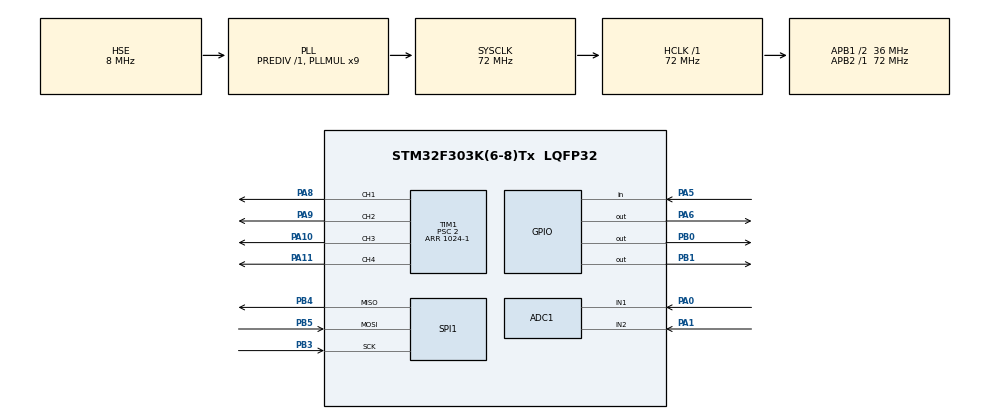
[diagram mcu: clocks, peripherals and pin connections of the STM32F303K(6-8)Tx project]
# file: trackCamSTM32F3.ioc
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ADC1.Channel-0\#ChannelRegularConversion=ADC_CHANNEL_1
ADC1.Channel-1\#ChannelRegularConversion=ADC_CHANNEL_2
ADC1.ClockPrescaler=ADC_CLOCK_SYNC_PCLK_DIV2
ADC1.ContinuousConvMode=ENABLE
ADC1.DMAAccessModeView=ENABLE
ADC1.DMAContinuousRequests=ENABLE
ADC1.EnableInjectedConversion=DISABLE
ADC1.NbrOfConversion=2
ADC1.NbrOfConversionFlag=1
ADC1.Offset-0\#ChannelRegularConversion=0
ADC1.Offset-1\#ChannelRegularConversion=0
ADC1.OffsetNumber-0\#ChannelRegularConversion=ADC_OFFSET_NONE
ADC1.OffsetNumber-1\#ChannelRegularConversion=ADC_OFFSET_NONE
ADC1.Overrun=ADC_OVR_DATA_PRESERVED
ADC1.Rank-0\#ChannelRegularConversion=1
ADC1.Rank-1\#ChannelRegularConversion=2
ADC1.SamplingTime-0\#ChannelRegularConversion=ADC_SAMPLETIME_19CYCLES_5
ADC1.SamplingTime-1\#ChannelRegularConversion=ADC_SAMPLETIME_19CYCLES_5
ADC1.SubFamily=STM32F303x8
ADC1.master=1
Dma.ADC1.0.Direction=DMA_PERIPH_TO_MEMORY
Dma.ADC1.0.Instance=DMA1_Channel1
Dma.ADC1.0.MemDataAlignment=DMA_MDATAALIGN_HALFWORD
Dma.ADC1.0.MemInc=DMA_MINC_ENABLE
Dma.ADC1.0.Mode=DMA_CIRCULAR
Dma.ADC1.0.PeriphDataAlignment=DMA_PDATAALIGN_HALFWORD
Dma.ADC1.0.PeriphInc=DMA_PINC_DISABLE
Dma.ADC1.0.Priority=DMA_PRIORITY_LOW
Dma.Request0=ADC1
Mcu.Family=STM32F3
Mcu.Name=STM32F303K(6-8)Tx
Mcu.Package=LQFP32
NVIC.DMA1_Channel1_IRQn=true\:0\:0\:false\:false\:true
NVIC.PriorityGroup=NVIC_PRIORITYGROUP_4
NVIC.TIM2_IRQn=true\:0\:0\:false\:false\:true
PA0.Mode=IN1-Single-Ended
PA0.Signal=ADC1_IN1
PA1.Mode=IN2-Single-Ended
PA1.Signal=ADC1_IN2
PA10.Signal=S_TIM1_CH3
PA11.Signal=S_TIM1_CH4
PA13.Mode=Serial_Wire
PA13.Signal=SYS_JTMS-SWDIO
PA14.Mode=Serial_Wire
PA14.Signal=SYS_JTCK-SWCLK
PA5.Signal=GPIO_Input
PA6.Signal=GPIO_Output
PA8.Signal=S_TIM1_CH1
PA9.Signal=S_TIM1_CH2
PB0.Signal=GPIO_Output
PB1.Signal=GPIO_Output
PB3.Mode=Full_Duplex_Slave
PB3.Signal=SPI1_SCK
PB4.Mode=Full_Duplex_Slave
PB4.Signal=SPI1_MISO
PB5.Mode=Full_Duplex_Slave
PB5.Signal=SPI1_MOSI
PF0\ /\ OSC_IN.Mode=HSE-External-Oscillator
PF0\ /\ OSC_IN.Signal=RCC_OSC_IN
PF1\ /\ OSC_OUT.Mode=HSE-External-Oscillator
PF1\ /\ OSC_OUT.Signal=RCC_OSC_OUT
ProjectManager.HeapSize=0x200
ProjectManager.StackSize=0x400
ProjectManager.TargetToolchain=SW4STM32
RCC.AHBFreq_Value=72000000
RCC.APB1CLKDivider=RCC_HCLK_DIV2
RCC.APB1Freq_Value=36000000
RCC.APB1TimFreq_Value=72000000
RCC.APB2Freq_Value=72000000
RCC.APB2TimFreq_Value=72000000
RCC.CortexFreq_Value=72000000
RCC.HCLKFreq_Value=72000000
RCC.HSE_VALUE=8000000
RCC.HSIState=RCC_HSI_ON
RCC.HSI_VALUE=8000000
RCC.PLLMUL=RCC_PLL_MUL9
RCC.PLLSourceVirtual=RCC_PLLSOURCE_HSE
RCC.SYSCLKFreq_VALUE=72000000
RCC.SYSCLKSourceVirtual=RCC_SYSCLKSOURCE_PLLCLK
SH.S_TIM1_CH1.0=TIM1_CH1,PWM Generation1 CH1
SH.S_TIM1_CH2.0=TIM1_CH2,PWM Generation2 CH2
SH.S_TIM1_CH3.0=TIM1_CH3,PWM Generation3 CH3
SH.S_TIM1_CH4.0=TIM1_CH4,PWM Generation4 CH4
SPI1.DataSize=SPI_DATASIZE_8BIT
SPI1.VirtualType=VM_SLAVE
TIM1.Channel-PWM\ Generation2\ CH2=TIM_CHANNEL_2
TIM1.Channel-PWM\ Generation3\ CH3=TIM_CHANNEL_3
TIM1.Channel-PWM\ Generation4\ CH4=TIM_CHANNEL_4
TIM1.Period=1024-1
TIM1.Prescaler=2
TIM2.Period=500-1
TIM2.Prescaler=7200
VP_TIM2_VS_ClockSourceINT.Mode=Internal
board=trackCamSTM32F3

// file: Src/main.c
/**
  ******************************************************************************
  * File Name          : main.c
  * Description        : Main program body
  ******************************************************************************
  *
  * COPYRIGHT(c) 2017 STMicroelectronics
  *
  * Redistribution and use in source and binary forms, with or without modification,
  * are permitted provided that the following conditions are met:
  *   1. Redistributions of source code must retain the above copyright notice,
  *      this list of conditions and the following disclaimer.
  *   2. Redistributions in binary form must reproduce the above copyright notice,
  *      this list of conditions and the following disclaimer in the documentation
  *      and/or other materials provided with the distribution.
  *   3. Neither the name of STMicroelectronics nor the names of its contributors
  *      may be used to endorse or promote products derived from this software
  *      without specific prior written permission.
  *
  * THIS SOFTWARE IS PROVIDED BY THE COPYRIGHT HOLDERS AND CONTRIBUTORS "AS IS"
  * AND ANY EXPRESS OR IMPLIED WARRANTIES, INCLUDING, BUT NOT LIMITED TO, THE
  * IMPLIED WARRANTIES OF MERCHANTABILITY AND FITNESS FOR A PARTICULAR PURPOSE ARE
  * DISCLAIMED. IN NO EVENT SHALL THE COPYRIGHT HOLDER OR CONTRIBUTORS BE LIABLE
  * FOR ANY DIRECT, INDIRECT, INCIDENTAL, SPECIAL, EXEMPLARY, OR CONSEQUENTIAL
  * DAMAGES (INCLUDING, BUT NOT LIMITED TO, PROCUREMENT OF SUBSTITUTE GOODS OR
  * SERVICES; LOSS OF USE, DATA, OR PROFITS; OR BUSINESS INTERRUPTION) HOWEVER
  * CAUSED AND ON ANY THEORY OF LIABILITY, WHETHER IN CONTRACT, STRICT LIABILITY,
  * OR TORT (INCLUDING NEGLIGENCE OR OTHERWISE) ARISING IN ANY WAY OUT OF THE USE
  * OF THIS SOFTWARE, EVEN IF ADVISED OF THE POSSIBILITY OF SUCH DAMAGE.
  *
  ******************************************************************************
  */
#include "main.h"
#include "stm32f3xx_hal.h"

/* USER CODE BEGIN Includes */
#include "TrackCam.h"
/* USER CODE END Includes */

ADC_HandleTypeDef hadc1;
DMA_HandleTypeDef hdma_adc1;

SPI_HandleTypeDef hspi1;

TIM_HandleTypeDef htim1;
TIM_HandleTypeDef htim2;

/* USER CODE BEGIN PV */
/* Private variables ---------------------------------------------------------*/

/* USER CODE END PV */

void SystemClock_Config(void);
void Error_Handler(void);
static void MX_GPIO_Init(void);
static void MX_DMA_Init(void);
static void MX_ADC1_Init(void);
static void MX_SPI1_Init(void);
static void MX_TIM1_Init(void);
static void MX_TIM2_Init(void);

void HAL_TIM_MspPostInit(TIM_HandleTypeDef *htim);

/* USER CODE BEGIN PFP */
/* Private function prototypes -----------------------------------------------*/

/* USER CODE END PFP */

int main(void)
{

  /* MCU Configuration----------------------------------------------------------*/

  /* Reset of all peripherals, Initializes the Flash interface and the Systick. */
  HAL_Init();

  /* Configure the system clock */
  SystemClock_Config();

  /* Initialize all configured peripherals */
  MX_GPIO_Init();
  MX_DMA_Init();
  MX_ADC1_Init();
  MX_SPI1_Init();
  MX_TIM1_Init();
  MX_TIM2_Init();

  /* Infinite loop */
  /* USER CODE BEGIN WHILE */
  TrackCamContext c;
  c.hadc = &hadc1;
  c.hspi = &hspi1;
  c.htimLed = &htim2;
  c.htimMotor = &htim1;
  trackCamMain(&c);
  /* USER CODE END WHILE */

}

/** System Clock Configuration
*/
void SystemClock_Config(void)
{

  RCC_OscInitTypeDef RCC_OscInitStruct;
  RCC_ClkInitTypeDef RCC_ClkInitStruct;
  RCC_PeriphCLKInitTypeDef PeriphClkInit;

    /**Initializes the CPU, AHB and APB busses clocks
    */
  RCC_OscInitStruct.OscillatorType = RCC_OSCILLATORTYPE_HSE;
  RCC_OscInitStruct.HSEState = RCC_HSE_ON;
  RCC_OscInitStruct.HSEPredivValue = RCC_HSE_PREDIV_DIV1;
  RCC_OscInitStruct.HSIState = RCC_HSI_ON;
  RCC_OscInitStruct.PLL.PLLState = RCC_PLL_ON;
  RCC_OscInitStruct.PLL.PLLSource = RCC_PLLSOURCE_HSE;
  RCC_OscInitStruct.PLL.PLLMUL = RCC_PLL_MUL9;
  if (HAL_RCC_OscConfig(&RCC_OscInitStruct) != HAL_OK)
  {
    Error_Handler();
  }

    /**Initializes the CPU, AHB and APB busses clocks
    */
  RCC_ClkInitStruct.ClockType = RCC_CLOCKTYPE_HCLK|RCC_CLOCKTYPE_SYSCLK
                              |RCC_CLOCKTYPE_PCLK1|RCC_CLOCKTYPE_PCLK2;
  RCC_ClkInitStruct.SYSCLKSource = RCC_SYSCLKSOURCE_PLLCLK;
  RCC_ClkInitStruct.AHBCLKDivider = RCC_SYSCLK_DIV1;
  RCC_ClkInitStruct.APB1CLKDivider = RCC_HCLK_DIV2;
  RCC_ClkInitStruct.APB2CLKDivider = RCC_HCLK_DIV1;

  if (HAL_RCC_ClockConfig(&RCC_ClkInitStruct, FLASH_LATENCY_2) != HAL_OK)
  {
    Error_Handler();
  }

  PeriphClkInit.PeriphClockSelection = RCC_PERIPHCLK_TIM1;
  PeriphClkInit.Tim1ClockSelection = RCC_TIM1CLK_HCLK;
  if (HAL_RCCEx_PeriphCLKConfig(&PeriphClkInit) != HAL_OK)
  {
    Error_Handler();
  }

    /**Configure the Systick interrupt time
    */
  HAL_SYSTICK_Config(HAL_RCC_GetHCLKFreq()/1000);

    /**Configure the Systick
    */
  HAL_SYSTICK_CLKSourceConfig(SYSTICK_CLKSOURCE_HCLK);

  /* SysTick_IRQn interrupt configuration */
  HAL_NVIC_SetPriority(SysTick_IRQn, 0, 0);
}

/* ADC1 init function */
static void MX_ADC1_Init(void)
{

  ADC_MultiModeTypeDef multimode;
  ADC_ChannelConfTypeDef sConfig;

    /**Common config
    */
  hadc1.Instance = ADC1;
  hadc1.Init.ClockPrescaler = ADC_CLOCK_SYNC_PCLK_DIV2;
  hadc1.Init.Resolution = ADC_RESOLUTION_12B;
  hadc1.Init.ScanConvMode = ADC_SCAN_ENABLE;
  hadc1.Init.ContinuousConvMode = ENABLE;
  hadc1.Init.DiscontinuousConvMode = DISABLE;
  hadc1.Init.ExternalTrigConvEdge = ADC_EXTERNALTRIGCONVEDGE_NONE;
  hadc1.Init.ExternalTrigConv = ADC_SOFTWARE_START;
  hadc1.Init.DataAlign = ADC_DATAALIGN_RIGHT;
  hadc1.Init.NbrOfConversion = 2;
  hadc1.Init.DMAContinuousRequests = ENABLE;
  hadc1.Init.EOCSelection = ADC_EOC_SINGLE_CONV;
  hadc1.Init.LowPowerAutoWait = DISABLE;
  hadc1.Init.Overrun = ADC_OVR_DATA_PRESERVED;
  if (HAL_ADC_Init(&hadc1) != HAL_OK)
  {
    Error_Handler();
  }

    /**Configure the ADC multi-mode
    */
  multimode.DMAAccessMode = ADC_DMAACCESSMODE_12_10_BITS;
  multimode.TwoSamplingDelay = ADC_TWOSAMPLINGDELAY_1CYCLE;
  if (HAL_ADCEx_MultiModeConfigChannel(&hadc1, &multimode) != HAL_OK)
  {
    Error_Handler();
  }

    /**Configure Regular Channel
    */
  sConfig.Channel = ADC_CHANNEL_1;
  sConfig.Rank = 1;
  sConfig.SingleDiff = ADC_SINGLE_ENDED;
  sConfig.SamplingTime = ADC_SAMPLETIME_19CYCLES_5;
  sConfig.OffsetNumber = ADC_OFFSET_NONE;
  sConfig.Offset = 0;
  if (HAL_ADC_ConfigChannel(&hadc1, &sConfig) != HAL_OK)
  {
    Error_Handler();
  }

    /**Configure Regular Channel
    */
  sConfig.Channel = ADC_CHANNEL_2;
  sConfig.Rank = 2;
  if (HAL_ADC_ConfigChannel(&hadc1, &sConfig) != HAL_OK)
  {
    Error_Handler();
  }

}

/* SPI1 init function */
static void MX_SPI1_Init(void)
{

  hspi1.Instance = SPI1;
  hspi1.Init.Mode = SPI_MODE_SLAVE;
  hspi1.Init.Direction = SPI_DIRECTION_2LINES;
  hspi1.Init.DataSize = SPI_DATASIZE_8BIT;
  hspi1.Init.CLKPolarity = SPI_POLARITY_LOW;
  hspi1.Init.CLKPhase = SPI_PHASE_1EDGE;
  hspi1.Init.NSS = SPI_NSS_SOFT;
  hspi1.Init.FirstBit = SPI_FIRSTBIT_MSB;
  hspi1.Init.TIMode = SPI_TIMODE_DISABLE;
  hspi1.Init.CRCCalculation = SPI_CRCCALCULATION_DISABLE;
  hspi1.Init.CRCPolynomial = 7;
  hspi1.Init.CRCLength = SPI_CRC_LENGTH_DATASIZE;
  hspi1.Init.NSSPMode = SPI_NSS_PULSE_DISABLE;
  if (HAL_SPI_Init(&hspi1) != HAL_OK)
  {
    Error_Handler();
  }

}

/* TIM1 init function */
static void MX_TIM1_Init(void)
{

  TIM_MasterConfigTypeDef sMasterConfig;
  TIM_OC_InitTypeDef sConfigOC;
  TIM_BreakDeadTimeConfigTypeDef sBreakDeadTimeConfig;

  htim1.Instance = TIM1;
  htim1.Init.Prescaler = 2;
  htim1.Init.CounterMode = TIM_COUNTERMODE_UP;
  htim1.Init.Period = 1024-1;
  htim1.Init.ClockDivision = TIM_CLOCKDIVISION_DIV1;
  htim1.Init.RepetitionCounter = 0;
  htim1.Init.AutoReloadPreload = TIM_AUTORELOAD_PRELOAD_DISABLE;
  if (HAL_TIM_PWM_Init(&htim1) != HAL_OK)
  {
    Error_Handler();
  }

  sMasterConfig.MasterOutputTrigger = TIM_TRGO_RESET;
  sMasterConfig.MasterOutputTrigger2 = TIM_TRGO2_RESET;
  sMasterConfig.MasterSlaveMode = TIM_MASTERSLAVEMODE_DISABLE;
  if (HAL_TIMEx_MasterConfigSynchronization(&htim1, &sMasterConfig) != HAL_OK)
  {
    Error_Handler();
  }

  sConfigOC.OCMode = TIM_OCMODE_PWM1;
  sConfigOC.Pulse = 0;
  sConfigOC.OCPolarity = TIM_OCPOLARITY_HIGH;
  sConfigOC.OCNPolarity = TIM_OCNPOLARITY_HIGH;
  sConfigOC.OCFastMode = TIM_OCFAST_DISABLE;
  sConfigOC.OCIdleState = TIM_OCIDLESTATE_RESET;
  sConfigOC.OCNIdleState = TIM_OCNIDLESTATE_RESET;
  if (HAL_TIM_PWM_ConfigChannel(&htim1, &sConfigOC, TIM_CHANNEL_1) != HAL_OK)
  {
    Error_Handler();
  }

  if (HAL_TIM_PWM_ConfigChannel(&htim1, &sConfigOC, TIM_CHANNEL_2) != HAL_OK)
  {
    Error_Handler();
  }

  if (HAL_TIM_PWM_ConfigChannel(&htim1, &sConfigOC, TIM_CHANNEL_3) != HAL_OK)
  {
    Error_Handler();
  }

  if (HAL_TIM_PWM_ConfigChannel(&htim1, &sConfigOC, TIM_CHANNEL_4) != HAL_OK)
  {
    Error_Handler();
  }

  sBreakDeadTimeConfig.OffStateRunMode = TIM_OSSR_DISABLE;
  sBreakDeadTimeConfig.OffStateIDLEMode = TIM_OSSI_DISABLE;
  sBreakDeadTimeConfig.LockLevel = TIM_LOCKLEVEL_OFF;
  sBreakDeadTimeConfig.DeadTime = 0;
  sBreakDeadTimeConfig.BreakState = TIM_BREAK_DISABLE;
  sBreakDeadTimeConfig.BreakPolarity = TIM_BREAKPOLARITY_HIGH;
  sBreakDeadTimeConfig.BreakFilter = 0;
  sBreakDeadTimeConfig.Break2State = TIM_BREAK2_DISABLE;
  sBreakDeadTimeConfig.Break2Polarity = TIM_BREAK2POLARITY_HIGH;
  sBreakDeadTimeConfig.Break2Filter = 0;
  sBreakDeadTimeConfig.AutomaticOutput = TIM_AUTOMATICOUTPUT_DISABLE;
  if (HAL_TIMEx_ConfigBreakDeadTime(&htim1, &sBreakDeadTimeConfig) != HAL_OK)
  {
    Error_Handler();
  }

  HAL_TIM_MspPostInit(&htim1);

}

/* TIM2 init function */
static void MX_TIM2_Init(void)
{

  TIM_ClockConfigTypeDef sClockSourceConfig;
  TIM_MasterConfigTypeDef sMasterConfig;

  htim2.Instance = TIM2;
  htim2.Init.Prescaler = 7200;
  htim2.Init.CounterMode = TIM_COUNTERMODE_UP;
  htim2.Init.Period = 500-1;
  htim2.Init.ClockDivision = TIM_CLOCKDIVISION_DIV1;
  htim2.Init.AutoReloadPreload = TIM_AUTORELOAD_PRELOAD_DISABLE;
  if (HAL_TIM_Base_Init(&htim2) != HAL_OK)
  {
    Error_Handler();
  }

  sClockSourceConfig.ClockSource = TIM_CLOCKSOURCE_INTERNAL;
  if (HAL_TIM_ConfigClockSource(&htim2, &sClockSourceConfig) != HAL_OK)
  {
    Error_Handler();
  }

  sMasterConfig.MasterOutputTrigger = TIM_TRGO_RESET;
  sMasterConfig.MasterSlaveMode = TIM_MASTERSLAVEMODE_DISABLE;
  if (HAL_TIMEx_MasterConfigSynchronization(&htim2, &sMasterConfig) != HAL_OK)
  {
    Error_Handler();
  }

}

static void MX_DMA_Init(void)
{
  /* DMA controller clock enable */
  __HAL_RCC_DMA1_CLK_ENABLE();

  /* DMA interrupt init */
  /* DMA1_Channel1_IRQn interrupt configuration */
  HAL_NVIC_SetPriority(DMA1_Channel1_IRQn, 0, 0);
  HAL_NVIC_EnableIRQ(DMA1_Channel1_IRQn);

}

/** Configure pins as
        * Analog
        * Input
        * Output
        * EVENT_OUT
        * EXTI
*/
static void MX_GPIO_Init(void)
{

  GPIO_InitTypeDef GPIO_InitStruct;

  /* GPIO Ports Clock Enable */
  __HAL_RCC_GPIOF_CLK_ENABLE();
  __HAL_RCC_GPIOA_CLK_ENABLE();
  __HAL_RCC_GPIOB_CLK_ENABLE();

  /*Configure GPIO pin Output Level */
  HAL_GPIO_WritePin(GPIOA, GPIO_PIN_6, GPIO_PIN_RESET);

  /*Configure GPIO pin Output Level */
  HAL_GPIO_WritePin(GPIOB, GPIO_PIN_0|GPIO_PIN_1, GPIO_PIN_RESET);

  /*Configure GPIO pin : PA5 */
  GPIO_InitStruct.Pin = GPIO_PIN_5;
  GPIO_InitStruct.Mode = GPIO_MODE_INPUT;
  GPIO_InitStruct.Pull = GPIO_NOPULL;
  HAL_GPIO_Init(GPIOA, &GPIO_InitStruct);

  /*Configure GPIO pin : PA6 */
  GPIO_InitStruct.Pin = GPIO_PIN_6;
  GPIO_InitStruct.Mode = GPIO_MODE_OUTPUT_PP;
  GPIO_InitStruct.Pull = GPIO_NOPULL;
  GPIO_InitStruct.Speed = GPIO_SPEED_FREQ_LOW;
  HAL_GPIO_Init(GPIOA, &GPIO_InitStruct);

  /*Configure GPIO pins : PB0 PB1 */
  GPIO_InitStruct.Pin = GPIO_PIN_0|GPIO_PIN_1;
  GPIO_InitStruct.Mode = GPIO_MODE_OUTPUT_PP;
  GPIO_InitStruct.Pull = GPIO_NOPULL;
  GPIO_InitStruct.Speed = GPIO_SPEED_FREQ_LOW;
  HAL_GPIO_Init(GPIOB, &GPIO_InitStruct);

}

void Error_Handler(void)
{
  /* USER CODE BEGIN Error_Handler */
  /* User can add his own implementation to report the HAL error return state */
    trackCamErrorHandler();
  /* USER CODE END Error_Handler */
}

/************************ (C) COPYRIGHT STMicroelectronics *****END OF FILE****/
